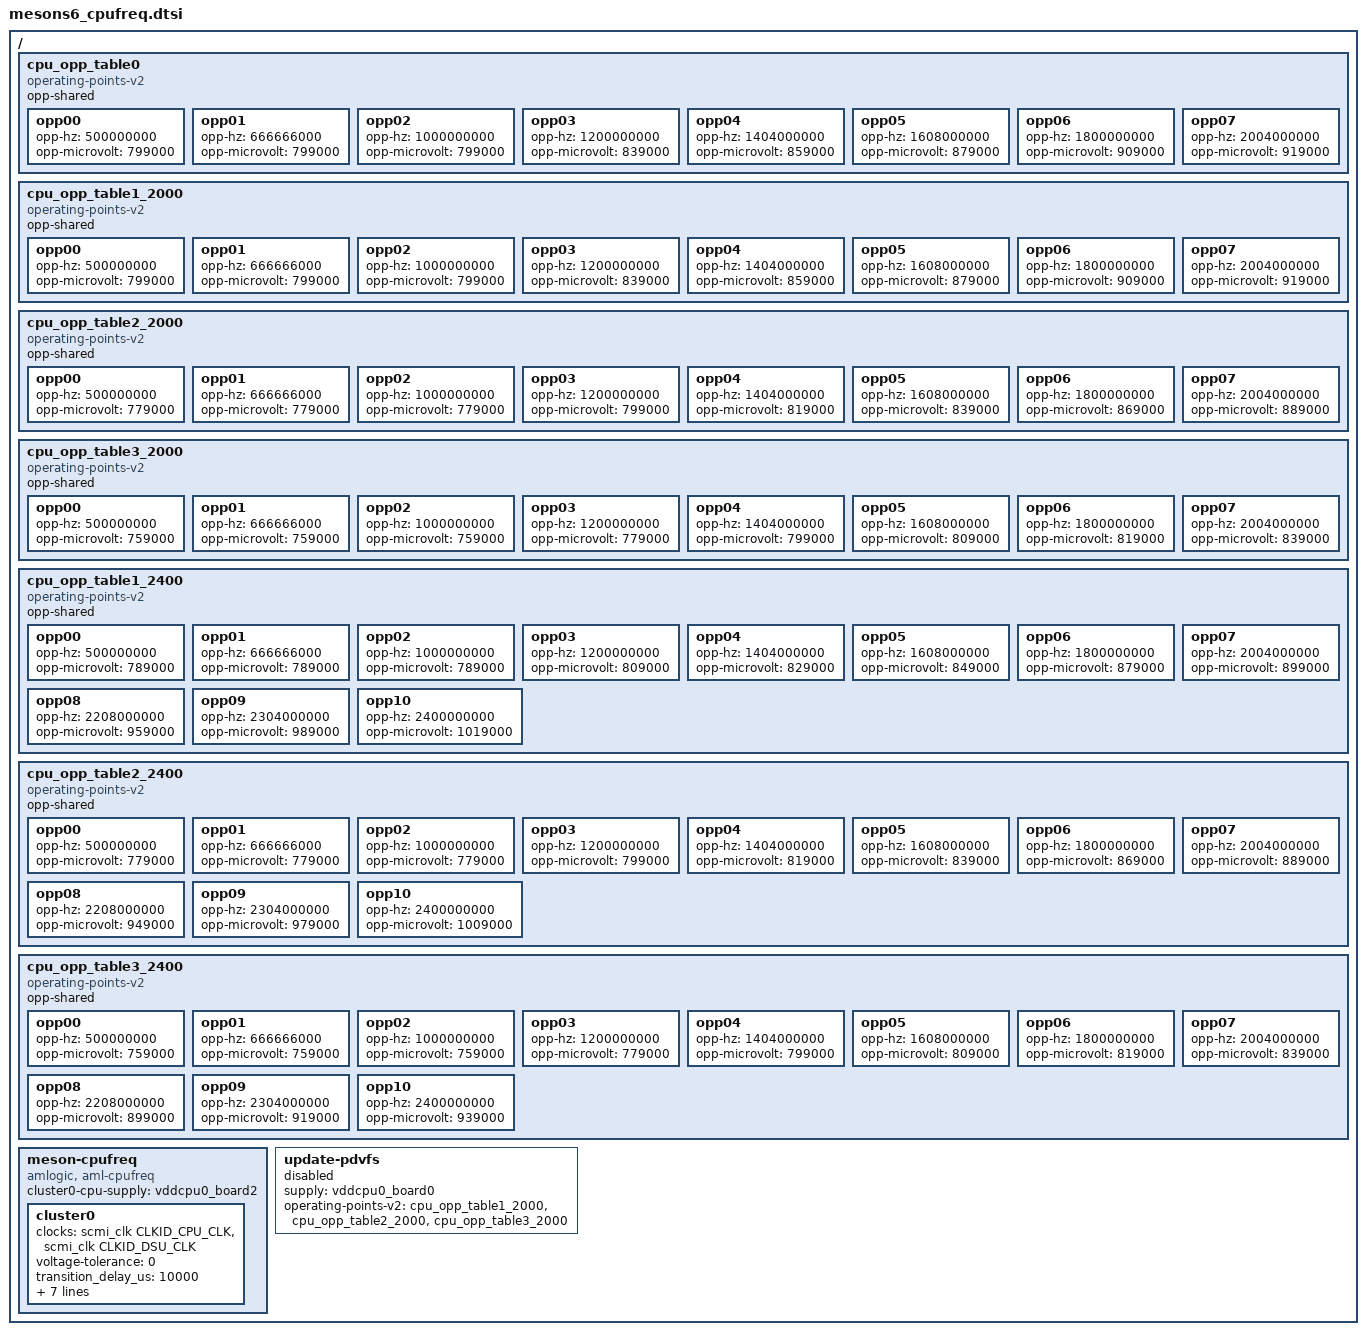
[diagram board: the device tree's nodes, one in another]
// SPDX-License-Identifier: (GPL-2.0+ OR MIT)
/*
 * Copyright (c) 2019 Amlogic, Inc. All rights reserved.
 */
/ {
	cpu_opp_table0: cpu_opp_table0 {
		compatible = "operating-points-v2";
		opp-shared;

		opp00 {
			opp-hz = /bits/ 64 <500000000>;
			opp-microvolt = <799000>;
		};
		opp01 {
			opp-hz = /bits/ 64 <666666000>;
			opp-microvolt = <799000>;
		};
		opp02 {
			opp-hz = /bits/ 64 <1000000000>;
			opp-microvolt = <799000>;
		};
		opp03 {
			opp-hz = /bits/ 64 <1200000000>;
			opp-microvolt = <839000>;
		};
		opp04 {
			opp-hz = /bits/ 64 <1404000000>;
			opp-microvolt = <859000>;
		};
		opp05 {
			opp-hz = /bits/ 64 <1608000000>;
			opp-microvolt = <879000>;
		};
		opp06 {
			opp-hz = /bits/ 64 <1800000000>;
			opp-microvolt = <909000>;
		};
		opp07 {
			opp-hz = /bits/ 64 <2004000000>;
			opp-microvolt = <919000>;
		};
	};

	cpu_opp_table1_2000: cpu_opp_table1_2000 {
		compatible = "operating-points-v2";
		opp-shared;

		opp00 {
			opp-hz = /bits/ 64 <500000000>;
			opp-microvolt = <799000>;
		};
		opp01 {
			opp-hz = /bits/ 64 <666666000>;
			opp-microvolt = <799000>;
		};
		opp02 {
			opp-hz = /bits/ 64 <1000000000>;
			opp-microvolt = <799000>;
		};
		opp03 {
			opp-hz = /bits/ 64 <1200000000>;
			opp-microvolt = <839000>;
		};
		opp04 {
			opp-hz = /bits/ 64 <1404000000>;
			opp-microvolt = <859000>;
		};
		opp05 {
			opp-hz = /bits/ 64 <1608000000>;
			opp-microvolt = <879000>;
		};
		opp06 {
			opp-hz = /bits/ 64 <1800000000>;
			opp-microvolt = <909000>;
		};
		opp07 {
			opp-hz = /bits/ 64 <2004000000>;
			opp-microvolt = <919000>;
		};
	};

	cpu_opp_table2_2000: cpu_opp_table2_2000 {
		compatible = "operating-points-v2";
		opp-shared;

		opp00 {
			opp-hz = /bits/ 64 <500000000>;
			opp-microvolt = <779000>;
		};
		opp01 {
			opp-hz = /bits/ 64 <666666000>;
			opp-microvolt = <779000>;
		};
		opp02 {
			opp-hz = /bits/ 64 <1000000000>;
			opp-microvolt = <779000>;
		};
		opp03 {
			opp-hz = /bits/ 64 <1200000000>;
			opp-microvolt = <799000>;
		};
		opp04 {
			opp-hz = /bits/ 64 <1404000000>;
			opp-microvolt = <819000>;
		};
		opp05 {
			opp-hz = /bits/ 64 <1608000000>;
			opp-microvolt = <839000>;
		};
		opp06 {
			opp-hz = /bits/ 64 <1800000000>;
			opp-microvolt = <869000>;
		};
		opp07 {
			opp-hz = /bits/ 64 <2004000000>;

			opp-microvolt = <889000>;
		};
	};

	cpu_opp_table3_2000: cpu_opp_table3_2000 {
		compatible = "operating-points-v2";
		opp-shared;

		opp00 {
			opp-hz = /bits/ 64 <500000000>;
			opp-microvolt = <759000>;
		};
		opp01 {
			opp-hz = /bits/ 64 <666666000>;
			opp-microvolt = <759000>;
		};
		opp02 {
			opp-hz = /bits/ 64 <1000000000>;
			opp-microvolt = <759000>;
		};
		opp03 {
			opp-hz = /bits/ 64 <1200000000>;
			opp-microvolt = <779000>;
		};
		opp04 {
			opp-hz = /bits/ 64 <1404000000>;
			opp-microvolt = <799000>;
		};
		opp05 {
			opp-hz = /bits/ 64 <1608000000>;
			opp-microvolt = <809000>;
		};
		opp06 {
			opp-hz = /bits/ 64 <1800000000>;
			opp-microvolt = <819000>;
		};
		opp07 {
			opp-hz = /bits/ 64 <2004000000>;

			opp-microvolt = <839000>;
		};
	};

	cpu_opp_table1_2400: cpu_opp_table1_2400 {
		compatible = "operating-points-v2";
		opp-shared;

		opp00 {
			opp-hz = /bits/ 64 <500000000>;
			opp-microvolt = <789000>;
		};
		opp01 {
			opp-hz = /bits/ 64 <666666000>;
			opp-microvolt = <789000>;
		};
		opp02 {
			opp-hz = /bits/ 64 <1000000000>;
			opp-microvolt = <789000>;
		};
		opp03 {
			opp-hz = /bits/ 64 <1200000000>;
			opp-microvolt = <809000>;
		};
		opp04 {
			opp-hz = /bits/ 64 <1404000000>;
			opp-microvolt = <829000>;
		};
		opp05 {
			opp-hz = /bits/ 64 <1608000000>;
			opp-microvolt = <849000>;
		};
		opp06 {
			opp-hz = /bits/ 64 <1800000000>;
			opp-microvolt = <879000>;
		};
		opp07 {
			opp-hz = /bits/ 64 <2004000000>;
			opp-microvolt = <899000>;
		};
		opp08 {
			opp-hz = /bits/ 64 <2208000000>;
			opp-microvolt = <959000>;
		};
		opp09 {
			opp-hz = /bits/ 64 <2304000000>;
			opp-microvolt = <989000>;
		};
		opp10 {
			opp-hz = /bits/ 64 <2400000000>;
			opp-microvolt = <1019000>;
		};
	};

	cpu_opp_table2_2400: cpu_opp_table2_2400 {
		compatible = "operating-points-v2";
		opp-shared;

		opp00 {
			opp-hz = /bits/ 64 <500000000>;
			opp-microvolt = <779000>;
		};
		opp01 {
			opp-hz = /bits/ 64 <666666000>;
			opp-microvolt = <779000>;
		};
		opp02 {
			opp-hz = /bits/ 64 <1000000000>;
			opp-microvolt = <779000>;
		};
		opp03 {
			opp-hz = /bits/ 64 <1200000000>;
			opp-microvolt = <799000>;
		};
		opp04 {
			opp-hz = /bits/ 64 <1404000000>;
			opp-microvolt = <819000>;
		};
		opp05 {
			opp-hz = /bits/ 64 <1608000000>;
			opp-microvolt = <839000>;
		};
		opp06 {
			opp-hz = /bits/ 64 <1800000000>;
			opp-microvolt = <869000>;
		};
		opp07 {
			opp-hz = /bits/ 64 <2004000000>;

			opp-microvolt = <889000>;
		};
		opp08 {
			opp-hz = /bits/ 64 <2208000000>;
			opp-microvolt = <949000>;
		};
		opp09 {
			opp-hz = /bits/ 64 <2304000000>;
			opp-microvolt = <979000>;
		};
		opp10 {
			opp-hz = /bits/ 64 <2400000000>;
			opp-microvolt = <1009000>;
		};
	};

	cpu_opp_table3_2400: cpu_opp_table3_2400 {
		compatible = "operating-points-v2";
		opp-shared;

		opp00 {
			opp-hz = /bits/ 64 <500000000>;
			opp-microvolt = <759000>;
		};
		opp01 {
			opp-hz = /bits/ 64 <666666000>;
			opp-microvolt = <759000>;
		};
		opp02 {
			opp-hz = /bits/ 64 <1000000000>;
			opp-microvolt = <759000>;
		};
		opp03 {
			opp-hz = /bits/ 64 <1200000000>;
			opp-microvolt = <779000>;
		};
		opp04 {
			opp-hz = /bits/ 64 <1404000000>;
			opp-microvolt = <799000>;
		};
		opp05 {
			opp-hz = /bits/ 64 <1608000000>;
			opp-microvolt = <809000>;
		};
		opp06 {
			opp-hz = /bits/ 64 <1800000000>;
			opp-microvolt = <819000>;
		};
		opp07 {
			opp-hz = /bits/ 64 <2004000000>;

			opp-microvolt = <839000>;
		};
		opp08 {
			opp-hz = /bits/ 64 <2208000000>;
			opp-microvolt = <899000>;
		};
		opp09 {
			opp-hz = /bits/ 64 <2304000000>;
			opp-microvolt = <919000>;
		};
		opp10 {
			opp-hz = /bits/ 64 <2400000000>;
			opp-microvolt = <939000>;
		};
	};

	meson-cpufreq {
		compatible = "amlogic, aml-cpufreq";
		status = "okay";

		cluster0-cpu-supply = <&vddcpu0_board2>;

		cluster0 {
			clocks = <&scmi_clk CLKID_CPU_CLK>, <&scmi_clk CLKID_DSU_CLK>;
			clock-names = "cpuclk", "dsuclk";
			voltage-tolerance = <0>;
			transition_delay_us = <10000>;
			//skip_volt_scaling;
			cluster_cores = <0 1 2 3>;
			pdvfs_enabled;
			dsu-opp-table = <1200000 1000000>,
					 <1404000 1128000>,
					 <1608000 1296000>,
					 <1800000 1440000>,
					 <2004000 1608000>,
					 <2208000 1800000>,
					 <2304000 1848000>,
					 <2400000 1920000>;
		};
	};

	update-pdvfs {
		status = "disabled";
		supply = <&vddcpu0_board0>;
		operating-points-v2 = <&cpu_opp_table1_2000>,
						<&cpu_opp_table2_2000>,
						<&cpu_opp_table3_2000>;
	};
};/* end of / */

